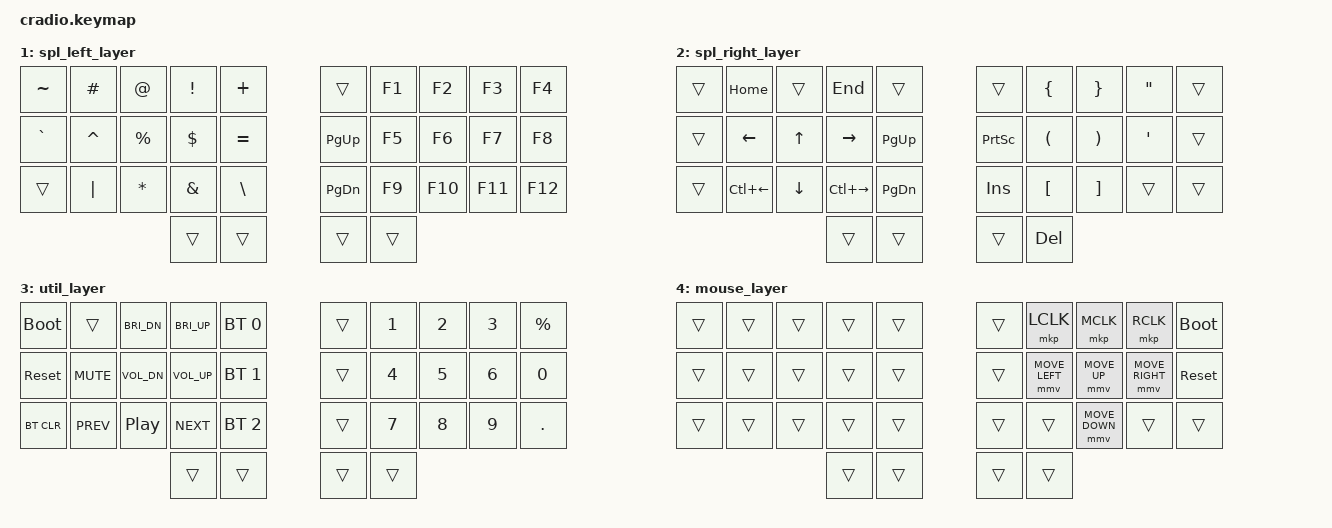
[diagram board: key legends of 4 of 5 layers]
// Copyright (c) 2022 The ZMK Contributors
// SPDX-License-Identifier: MIT

#include <behaviors.dtsi>
#include <dt-bindings/zmk/keys.h>
#include <dt-bindings/zmk/bt.h>
#include <dt-bindings/zmk/outputs.h>

#define ZMK_POINTING_DEFAULT_MOVE_VAL 1200

#include <dt-bindings/zmk/pointing.h>

// Home row mods macro
#define LHYP LG(LA(LS(LCTRL)))
#define RHYP RG(RA(RS(RCTRL)))
#define LHRM(k1,k2,k3,k4,k5) &mt LSHFT k1  &mt LALT k2  &mt LGUI k3  &mt LCTRL k4  &mt LHYP k5
// The right hand mod uses LALT as RALT is interpreted as ISO level 3 shift
#define RHRM(k1,k2,k3,k4,k5) &mt RHYP k1  &mt RCTRL k2  &mt RGUI k3  &mt LALT k4  &mt RSHFT k5

// Layers
#define COLEMAK 0
#define SPL_LEFT 1
#define SPL_RIGHT 2
#define UTIL 3
#define MOUSE 4

// Behaviour
#define BEHAVIOUR(b) &b {\
    flavor = "balanced";\
    tapping-term-ms = <140>;\
    quick-tap-ms = <100>;\
    global-quick-tap;\
}

BEHAVIOUR(lt);
BEHAVIOUR(mt);

// ZMK specific config, parsed differently from regular C
/ {
    combos {
        compatible = "zmk,combos";
        combo_esc {
            timeout-ms = <40>;
            key-positions = <13 16>;
            bindings = <&kp ESC>;
        };
        combo_minus {
            timeout-ms = <40>;
            key-positions = <12 17>;
            bindings = <&kp MINUS>;
        };
        combo_under {
            timeout-ms = <40>;
            key-positions = <11 18>;
            bindings = <&kp UNDER>;
        };
        combo_caps_word {
            timeout-ms = <40>;
            key-positions = <10 19>;
            bindings = <&caps_word>;
        };
        combo_caps_lock {
            timeout-ms = <40>;
            key-positions = <20 29>;
            bindings = <&kp CAPSLOCK>;
        };
        combo_ble {
            timeout-ms = <40>;
            key-positions = <0 9>;
            bindings = <&out OUT_TOG>;
        };
    };

    keymap {
        compatible = "zmk,keymap";
        default_layer {
            bindings = <
            &kp Q      &kp W      &kp F      &kp P      &kp G          &kp J      &kp L      &kp U      &kp Y      &kp SEMI
            LHRM(A,        R,         S,         T,         D)         RHRM(H,        N,         E,         I,         O)
            &kp Z      &kp X      &kp C      &kp V      &kp B          &kp K      &kp M      &kp COMMA  &kp DOT    &kp FSLH
                            &lt SPL_RIGHT SPACE  &lt UTIL TAB          &lt MOUSE ENTER  &lt SPL_LEFT BSPC
            >;
        };

        spl_left_layer {
            bindings = <
            &kp TILDE  &kp HASH   &kp AT     &kp EXCL   &kp PLUS       &trans     &kp F1     &kp F2     &kp F3     &kp F4
            &kp GRAVE  &kp CARET  &kp PRCNT  &kp DLLR   &kp EQUAL      &kp PG_UP  &kp F5     &kp F6     &kp F7     &kp F8
            &trans     &kp PIPE   &kp STAR   &kp AMPS   &kp BSLH       &kp PG_DN  &kp F9     &kp F10    &kp F11    &kp F12
                                             &trans     &trans         &trans     &trans
            >;
        };

        spl_right_layer {
            bindings = <
            &trans    &kp HOME     &trans     &kp END      &trans         &trans     &kp LBRC   &kp RBRC   &kp DQT    &trans
            &trans    &kp LEFT     &kp UP    &kp RIGHT     &kp PG_UP      &kp PSCRN  &kp LPAR   &kp RPAR   &kp SQT    &trans
            &trans  &kp LC(LEFT)  &kp DOWN  &kp LC(RIGHT)  &kp PG_DN      &kp INS    &kp LBKT   &kp RBKT   &trans     &trans
                                              &trans       &trans         &trans     &kp DEL
            >;
        };

        util_layer {
            bindings = <
            &bootloader  &trans    &kp C_BRI_DN &kp C_BRI_UP  &bt BT_SEL 0    &trans     &kp N1     &kp N2     &kp N3     &kp PRCNT
            &sys_reset  &kp C_MUTE &kp C_VOL_DN &kp C_VOL_UP  &bt BT_SEL 1    &trans     &kp N4     &kp N5     &kp N6     &kp N0
            &bt BT_CLR  &kp C_PREV   &kp C_PP    &kp C_NEXT   &bt BT_SEL 2    &trans     &kp N7     &kp N8     &kp N9     &kp DOT
                                                 &trans         &trans        &trans     &trans
            >;
        };

        mouse_layer {
            bindings = <
            &trans     &trans     &trans     &trans     &trans         &trans    &mkp LCLK      &mkp MCLK      &mkp RCLK     &bootloader
            &trans     &trans     &trans     &trans     &trans         &trans  &mmv MOVE_LEFT  &mmv MOVE_UP  &mmv MOVE_RIGHT &sys_reset
            &trans     &trans     &trans     &trans     &trans         &trans     &trans      &mmv MOVE_DOWN     &trans      &trans
                                             &trans     &trans         &trans     &trans
            >;
        };
    };
};
